# STM32L162ZET6 register map
File version: 1.0
Registers are 32-bit, access not given, reset 0x0 unless marked. A register's access mark holds for its fields unless they carry their own. Offsets are from the block's base; [hi:lo] are bit positions; {n}, {i} and the like mark numbered series.

## WWDG
Base 0x40002C00
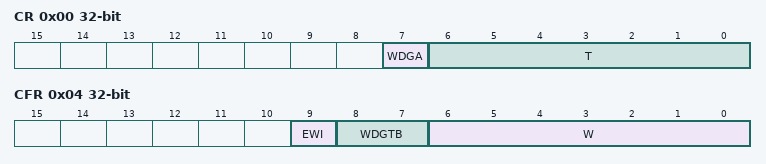
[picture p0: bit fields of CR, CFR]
0x00 CR
  [7] WDGA, [6:0] T
0x04 CFR
  [9] EWI, [8:7] WDGTB, [6:0] W
0x08 SR
  [0] EWIF

## IWDG
Base 0x40003000
0x00 KR
  [15:0] KEY
0x04 PR
  [2:0] PR
0x08 RLR
  [11:0] RL
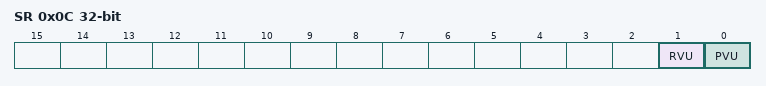
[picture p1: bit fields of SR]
0x0C SR
  [1] RVU, [0] PVU

## SPI2
Base 0x40003800
Same registers: SPI3 0x40003C00, SPI1 0x40013000
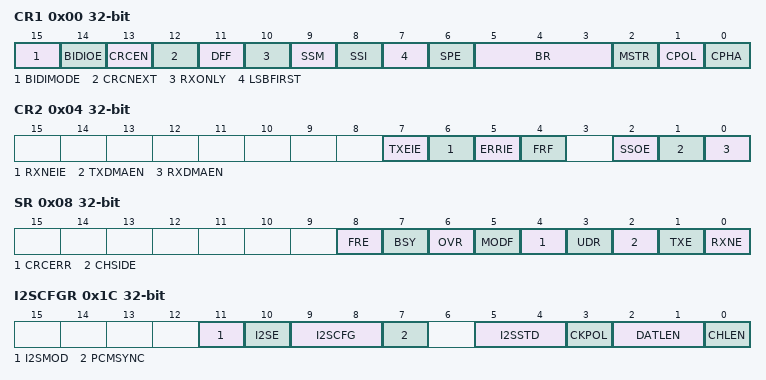
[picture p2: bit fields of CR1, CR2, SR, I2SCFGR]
0x00 CR1
  [15] BIDIMODE, [14] BIDIOE, [13] CRCEN, [12] CRCNEXT, [11] DFF, [10] RXONLY, [9] SSM, [8] SSI, [7] LSBFIRST, [6] SPE, [5:3] BR, [2] MSTR, [1] CPOL, [0] CPHA
0x04 CR2
  [7] TXEIE, [6] RXNEIE, [5] ERRIE, [4] FRF, [2] SSOE, [1] TXDMAEN, [0] RXDMAEN
0x08 SR
  [8] FRE, [7] BSY, [6] OVR, [5] MODF, [4] CRCERR, [3] UDR, [2] CHSIDE, [1] TXE, [0] RXNE
0x0C DR
  [15:0] DR
0x10 CRCPR
  [15:0] CRCPOLY
0x14 RXCRCR
  [15:0] RXCRC
0x18 TXCRCR
  [15:0] TXCRC
0x1C I2SCFGR
  [11] I2SMOD, [10] I2SE, [9:8] I2SCFG, [7] PCMSYNC, [5:4] I2SSTD, [3] CKPOL, [2:1] DATLEN, [0] CHLEN
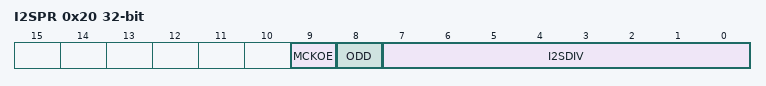
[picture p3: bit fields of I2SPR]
0x20 I2SPR
  [9] MCKOE, [8] ODD, [7:0] I2SDIV

## USART2
Base 0x40004400
Same registers: USART3 0x40004800, UART4 0x40004C00, UART5 0x40005000, USART1 0x40013800
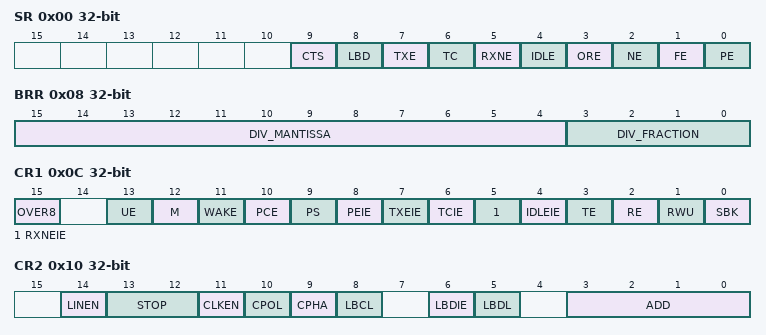
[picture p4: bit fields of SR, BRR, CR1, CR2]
0x00 SR
  [9] CTS, [8] LBD, [7] TXE, [6] TC, [5] RXNE, [4] IDLE, [3] ORE, [2] NE, [1] FE, [0] PE
0x04 DR
  [8:0] DR
0x08 BRR
  [15:4] DIV_MANTISSA, [3:0] DIV_FRACTION
0x0C CR1
  [15] OVER8, [13] UE, [12] M, [11] WAKE, [10] PCE, [9] PS, [8] PEIE, [7] TXEIE, [6] TCIE, [5] RXNEIE, [4] IDLEIE, [3] TE, [2] RE, [1] RWU, [0] SBK
0x10 CR2
  [14] LINEN, [13:12] STOP, [11] CLKEN, [10] CPOL, [9] CPHA, [8] LBCL, [6] LBDIE, [5] LBDL, [3:0] ADD
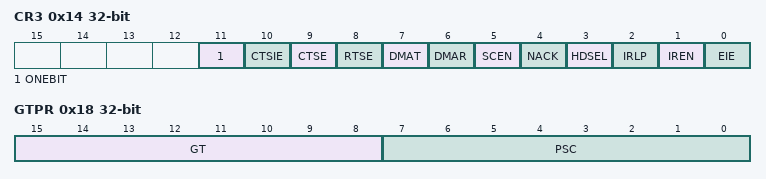
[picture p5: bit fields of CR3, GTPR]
0x14 CR3
  [11] ONEBIT, [10] CTSIE, [9] CTSE, [8] RTSE, [7] DMAT, [6] DMAR, [5] SCEN, [4] NACK, [3] HDSEL, [2] IRLP, [1] IREN, [0] EIE
0x18 GTPR
  [15:8] GT, [7:0] PSC

## I2C1
Base 0x40005400
Same registers: I2C2 0x40005800
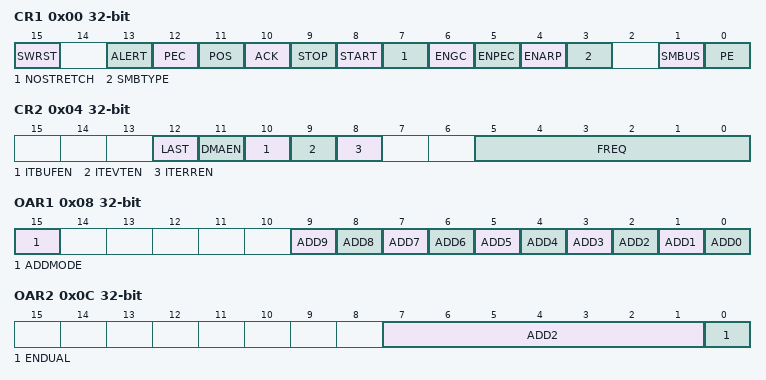
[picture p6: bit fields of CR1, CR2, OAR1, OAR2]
0x00 CR1
  [15] SWRST, [13] ALERT, [12] PEC, [11] POS, [10] ACK, [9] STOP, [8] START, [7] NOSTRETCH, [6] ENGC, [5] ENPEC, [4] ENARP, [3] SMBTYPE, [1] SMBUS, [0] PE
0x04 CR2
  [12] LAST, [11] DMAEN, [10] ITBUFEN, [9] ITEVTEN, [8] ITERREN, [5:0] FREQ
0x08 OAR1
  [15] ADDMODE, [n] ADD{n} (n=0..9)
0x0C OAR2
  [7:1] ADD2, [0] ENDUAL
0x10 DR
  [7:0] DR
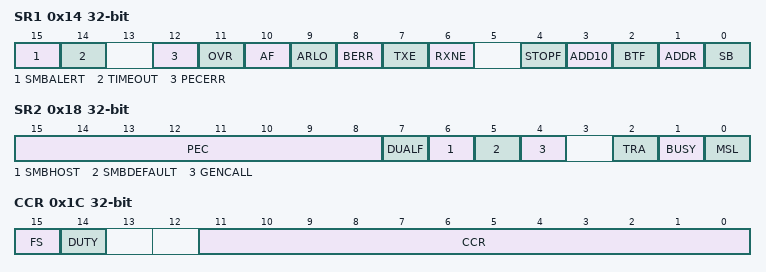
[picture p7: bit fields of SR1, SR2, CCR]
0x14 SR1
  [15] SMBALERT, [14] TIMEOUT, [12] PECERR, [11] OVR, [10] AF, [9] ARLO, [8] BERR, [7] TXE, [6] RXNE, [4] STOPF, [3] ADD10, [2] BTF, [1] ADDR, [0] SB
0x18 SR2
  [15:8] PEC, [7] DUALF, [6] SMBHOST, [5] SMBDEFAULT, [4] GENCALL, [2] TRA, [1] BUSY, [0] MSL
0x1C CCR
  [15] FS, [14] DUTY, [11:0] CCR
0x20 TRISE
  [5:0] TRISE

## USB
Base 0x40005C00
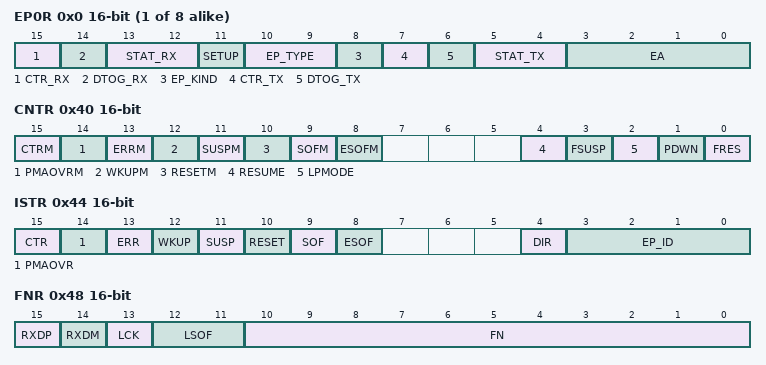
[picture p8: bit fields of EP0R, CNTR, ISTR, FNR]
{0x0+4i} EP{i}R 16-bit (i=0..7)
  [15] CTR_RX, [14] DTOG_RX, [13:12] STAT_RX, [11] SETUP, [10:9] EP_TYPE, [8] EP_KIND, [7] CTR_TX, [6] DTOG_TX, [5:4] STAT_TX, [3:0] EA
0x40 CNTR 16-bit
  [15] CTRM, [14] PMAOVRM, [13] ERRM, [12] WKUPM, [11] SUSPM, [10] RESETM, [9] SOFM, [8] ESOFM, [4] RESUME, [3] FSUSP, [2] LPMODE, [1] PDWN, [0] FRES
0x44 ISTR 16-bit
  [15] CTR, [14] PMAOVR, [13] ERR, [12] WKUP, [11] SUSP, [10] RESET, [9] SOF, [8] ESOF, [4] DIR, [3:0] EP_ID
0x48 FNR 16-bit
  [15] RXDP, [14] RXDM, [13] LCK, [12:11] LSOF, [10:0] FN
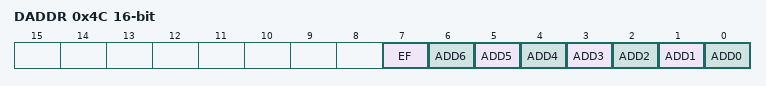
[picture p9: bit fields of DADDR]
0x4C DADDR 16-bit
  [7] EF, [n] ADD{n} (n=0..6)
0x50 BTABLE 16-bit
  [15:3] BTABLE

## PWR
Base 0x40007000
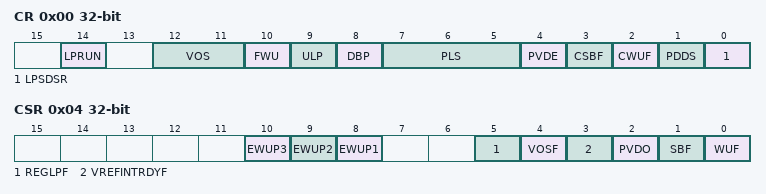
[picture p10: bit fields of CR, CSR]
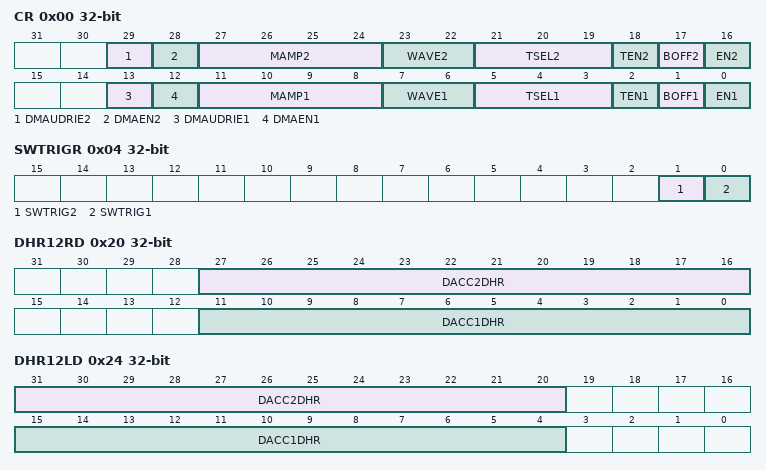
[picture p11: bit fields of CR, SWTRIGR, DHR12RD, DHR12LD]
0x00 CR
  [14] LPRUN, [12:11] VOS, [10] FWU, [9] ULP, [8] DBP, [7:5] PLS, [4] PVDE, [3] CSBF, [2] CWUF, [1] PDDS, [0] LPSDSR
0x04 CSR
  [10] EWUP3, [9] EWUP2, [8] EWUP1, [5] REGLPF, [4] VOSF, [3] VREFINTRDYF, [2] PVDO, [1] SBF, [0] WUF

## DAC1
Base 0x40007400
0x00 CR
  [29] DMAUDRIE2, [28] DMAEN2, [27:24] MAMP2, [23:22] WAVE2, [21:19] TSEL2, [18] TEN2, [17] BOFF2, [16] EN2, [13] DMAUDRIE1, [12] DMAEN1, [11:8] MAMP1, [7:6] WAVE1, [5:3] TSEL1, [2] TEN1, [1] BOFF1, [0] EN1
0x04 SWTRIGR
  [1] SWTRIG2, [0] SWTRIG1
0x08 DHR12R1
  [11:0] DACC1DHR
0x0C DHR12L1
  [15:4] DACC1DHR
0x10 DHR8R1
  [7:0] DACC1DHR
0x14 DHR12R2
  [11:0] DACC2DHR
0x18 DHR12L2
  [15:4] DACC2DHR
0x1C DHR8R2
  [7:0] DACC2DHR
0x20 DHR12RD
  [27:16] DACC2DHR, [11:0] DACC1DHR
0x24 DHR12LD
  [31:20] DACC2DHR, [15:4] DACC1DHR
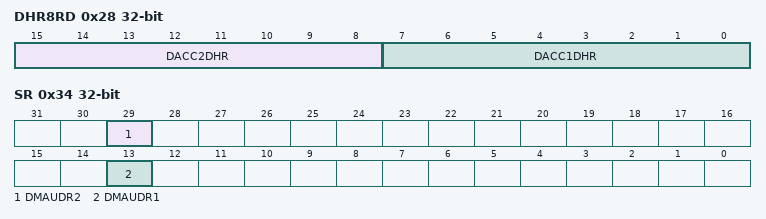
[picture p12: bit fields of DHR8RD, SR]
0x28 DHR8RD
  [15:8] DACC2DHR, [7:0] DACC1DHR
0x2C DOR1
  [11:0] DACC1DOR
0x30 DOR2
  [11:0] DACC2DOR
0x34 SR
  [29] DMAUDR2, [13] DMAUDR1
